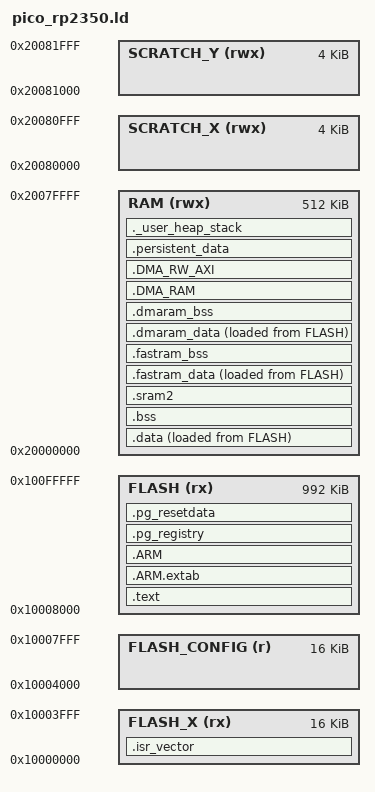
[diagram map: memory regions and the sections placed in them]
/* Specify the memory areas */
MEMORY
{
    FLASH_X (rx)      : ORIGIN = 0x10000000, LENGTH = 16K
    FLASH_CONFIG (r)  : ORIGIN = 0x10004000, LENGTH = 16K
    FLASH (rx)        : ORIGIN = 0x10008000, LENGTH = 992K
    RAM (rwx)         : ORIGIN = 0x20000000, LENGTH = 512K
    SCRATCH_X(rwx)    : ORIGIN = 0x20080000, LENGTH = 4k
    SCRATCH_Y(rwx)    : ORIGIN = 0x20081000, LENGTH = 4k
}

REGION_ALIAS("STACKRAM", RAM)
REGION_ALIAS("FASTRAM", RAM)
REGION_ALIAS("MOVABLE_FLASH", FLASH)

/* Entry Point */
ENTRY(Reset_Handler)

/* Highest address of the user mode stack */
_estack = ORIGIN(STACKRAM) + LENGTH(STACKRAM) - 8; /* Reserve 2 x 4bytes for info across reset */

/* Base address where the config is stored. */
__config_start = ORIGIN(FLASH_CONFIG);
__config_end = ORIGIN(FLASH_CONFIG) + LENGTH(FLASH_CONFIG);

/* Generate a link error if heap and stack don't fit into RAM */
_Min_Heap_Size = 0;      /* required amount of heap  */
_Min_Stack_Size = 0x800; /* required amount of stack */

/* Define output sections */
SECTIONS
{
  /* The startup code goes first into FLASH_X */
  .isr_vector :
  {
    . = ALIGN(512);
    PROVIDE (isr_vector_table_base = .);
    KEEP(*(.isr_vector)) /* Startup code */
    . = ALIGN(4);
  } >FLASH_X

  /* The program code and other data goes into FLASH */
  .text :
  {
    . = ALIGN(4);
    *(.text)           /* .text sections (code) */
    *(.text*)          /* .text* sections (code) */
    *(.rodata)         /* .rodata sections (constants, strings, etc.) */
    *(.rodata*)        /* .rodata* sections (constants, strings, etc.) */
    *(.glue_7)         /* glue arm to thumb code */
    *(.glue_7t)        /* glue thumb to arm code */
    *(.eh_frame)

    KEEP (*(.init))
    KEEP (*(.fini))

    . = ALIGN(4);
    _etext = .;        /* define a global symbols at end of code */
  } >FLASH

  .ARM.extab   :
  {
    *(.ARM.extab* .gnu.linkonce.armextab.*)
  } >FLASH

  .ARM :
  {
    __exidx_start = .;
    *(.ARM.exidx*) __exidx_end = .;
  } >FLASH

  .pg_registry :
  {
    PROVIDE_HIDDEN (__pg_registry_start = .);
    KEEP (*(.pg_registry))
    KEEP (*(SORT(.pg_registry.*)))
    PROVIDE_HIDDEN (__pg_registry_end = .);
  } >FLASH

  .pg_resetdata :
  {
    PROVIDE_HIDDEN (__pg_resetdata_start = .);
    KEEP (*(.pg_resetdata))
    PROVIDE_HIDDEN (__pg_resetdata_end = .);
  } >FLASH

  /* used by the startup to initialize data */
  _sidata = LOADADDR(.data);

  /* Initialized data sections goes into RAM, load LMA copy after code */
  .data :
  {
    . = ALIGN(4);
    _sdata = .;        /* create a global symbol at data start */
    *(.data)           /* .data sections */
    *(.data*)          /* .data* sections */

    . = ALIGN(4);
    _edata = .;        /* define a global symbol at data end */
  } >RAM AT >FLASH

  /* Uninitialized data section */
  . = ALIGN(4);
  .bss (NOLOAD) :
  {
    /* This is used by the startup in order to initialize the .bss secion */
    _sbss = .;         /* define a global symbol at bss start */
    __bss_start__ = _sbss;
    *(.bss)
    *(SORT_BY_ALIGNMENT(.bss*))
    *(COMMON)

    . = ALIGN(4);
    _ebss = .;         /* define a global symbol at bss end */
    __bss_end__ = _ebss;
  } >RAM

  /* Uninitialized data section */
  . = ALIGN(4);
  .sram2 (NOLOAD) :
  {
    /* This is used by the startup in order to initialize the .sram2 secion */
    _ssram2 = .;         /* define a global symbol at sram2 start */
    __sram2_start__ = _ssram2;
    *(.sram2)
    *(SORT_BY_ALIGNMENT(.sram2*))

    . = ALIGN(4);
    _esram2 = .;         /* define a global symbol at sram2 end */
    __sram2_end__ = _esram2;
  } >RAM

  /* used during startup to initialized fastram_data */
  _sfastram_idata = LOADADDR(.fastram_data);

  /* Initialized FAST_DATA section for unsuspecting developers */
  .fastram_data :
  {
    . = ALIGN(4);
    _sfastram_data = .;        /* create a global symbol at data start */
    *(.fastram_data)           /* .data sections */
    *(.fastram_data*)          /* .data* sections */

    . = ALIGN(4);
    _efastram_data = .;        /* define a global symbol at data end */
  } >FASTRAM AT >FLASH

  . = ALIGN(4);
  .fastram_bss (NOLOAD) :
  {
    _sfastram_bss = .;
    __fastram_bss_start__ = _sfastram_bss;
    *(.fastram_bss)
    *(SORT_BY_ALIGNMENT(.fastram_bss*))

    . = ALIGN(4);
    _efastram_bss = .;
    __fastram_bss_end__ = _efastram_bss;
  } >FASTRAM

  /* used during startup to initialized dmaram_data */
  _sdmaram_idata = LOADADDR(.dmaram_data);

  . = ALIGN(32);
  .dmaram_data :
  {
    PROVIDE(dmaram_start = .);
    _sdmaram = .;
    _dmaram_start__ = _sdmaram;
    _sdmaram_data = .;        /* create a global symbol at data start */
    *(.dmaram_data)           /* .data sections */
    *(.dmaram_data*)          /* .data* sections */
    . = ALIGN(32);
    _edmaram_data = .;        /* define a global symbol at data end */
  } >RAM AT >FLASH

  . = ALIGN(32);
  .dmaram_bss (NOLOAD) :
  {
    _sdmaram_bss = .;
    __dmaram_bss_start__ = _sdmaram_bss;
    *(.dmaram_bss)
    *(SORT_BY_ALIGNMENT(.dmaram_bss*))
    . = ALIGN(32);
    _edmaram_bss = .;
    __dmaram_bss_end__ = _edmaram_bss;
  } >RAM

  . = ALIGN(32);
  .DMA_RAM (NOLOAD) :
  {
    KEEP(*(.DMA_RAM))
    PROVIDE(dmaram_end = .);
    _edmaram = .;
    _dmaram_end__ = _edmaram;
  } >RAM

  .DMA_RW_AXI (NOLOAD) :
  {
    . = ALIGN(32);
    PROVIDE(dmarwaxi_start = .);
    _sdmarwaxi = .;
    _dmarwaxi_start__ = _sdmarwaxi;
    KEEP(*(.DMA_RW_AXI))
    PROVIDE(dmarwaxi_end = .);
    _edmarwaxi = .;
    _dmarwaxi_end__ = _edmarwaxi;
  } >RAM

  .persistent_data (NOLOAD) :
  {
    __persistent_data_start__ = .;
    *(.persistent_data)
    . = ALIGN(4);
    __persistent_data_end__ = .;
  } >RAM


  /* User_heap_stack section, used to check that there is enough RAM left */
  _heap_stack_end = ORIGIN(STACKRAM)+LENGTH(STACKRAM) - 8; /* 8 bytes to allow for alignment */
  _heap_stack_begin = _heap_stack_end - _Min_Stack_Size  - _Min_Heap_Size;
  . = _heap_stack_begin;
  ._user_heap_stack :
  {
    . = ALIGN(4);
    PROVIDE ( end = . );
    PROVIDE ( _end = . );
    . = . + _Min_Heap_Size;
    . = . + _Min_Stack_Size;
    . = ALIGN(4);
  } >STACKRAM = 0xa5

  /* Remove information from the standard libraries */
  /DISCARD/ :
  {
    libc.a ( * )
    libm.a ( * )
    libgcc.a ( * )
  }

  .ARM.attributes 0 : { *(.ARM.attributes) }
}
